AUTOSAR XML (schema 4-3-0)
package /Impl_SWC_CDD_ARPkg
  swc implementation Impl_SWC_CDD_type: programming-language=C, sw-version=1.0.0, vendor-id=0, behavior=SWC_CDD_type_IB
    code-descriptors:
      code SRC: artifact-descriptors=autosar-engineering-object={short-label=EngObject, category=SWSRC}
    resource consumption ResourceConsumption
      memory section Mem_SWC_CDD_CODE: size=0, sw-addrmethod=CODE, symbol=CODE
package /SWC_CDD_ARPkg
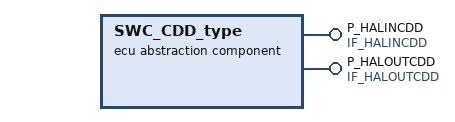
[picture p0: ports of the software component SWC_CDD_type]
  ecu abstraction sw component type SWC_CDD_type
    provide port P_HALINCDD: provided-interface=IF_HALINCDD
    provide port P_HALOUTCDD: provided-interface=IF_HALOUTCDD
    behavior SWC_CDD_type_IB: handle-termination-and-restart=NO-SUPPORT
      61 x operation invoked event:
        oie_P_HALINCDD_CSOP_apsGetDidRequest: start-on-event=run_HALINCDD_apsGetDidRequest, operation=P_HALINCDD.CSOP_apsGetDidRequest
        oie_P_HALINCDD_CSOP_dkcGetDidRequest: start-on-event=run_HALINCDD_dkcGetDidRequest, operation=P_HALINCDD.CSOP_dkcGetDidRequest
        oie_P_HALINCDD_CSOP_zevGetDidRequest: start-on-event=run_HALINCDD_zevGetDidRequest, operation=P_HALINCDD.CSOP_zevGetDidRequest
        oie_P_HALINCDD_CSOP_tpmGetDidRequest: start-on-event=run_HALINCDD_tpmGetDidRequest, operation=P_HALINCDD.CSOP_tpmGetDidRequest
        oie_P_HALINCDD_CSOP_bcmGetDidRequest: start-on-event=run_HALINCDD_bcmGetDidRequest, operation=P_HALINCDD.CSOP_bcmGetDidRequest
        oie_P_HALINCDD_CSOP_vcuGetDidRequest: start-on-event=run_HALINCDD_vcuGetDidRequest, operation=P_HALINCDD.CSOP_vcuGetDidRequest
        oie_P_HALINCDD_CSOP_dkcIsDidRequested: start-on-event=run_HALINCDD_dkcIsDidRequested, operation=P_HALINCDD.CSOP_dkcIsDidRequested
        oie_P_HALINCDD_CSOP_zevIsDidRequested: start-on-event=run_HALINCDD_zevIsDidRequested, operation=P_HALINCDD.CSOP_zevIsDidRequested
        oie_P_HALINCDD_CSOP_apsIsDidRequested: start-on-event=run_HALINCDD_apsIsDidRequested, operation=P_HALINCDD.CSOP_apsIsDidRequested
        oie_P_HALINCDD_CSOP_tpmIsDidRequested: start-on-event=run_HALINCDD_tpmIsDidRequested, operation=P_HALINCDD.CSOP_tpmIsDidRequested
        oie_P_HALINCDD_CSOP_bcmIsDidRequested: start-on-event=run_HALINCDD_bcmIsDidRequested, operation=P_HALINCDD.CSOP_bcmIsDidRequested
        oie_P_HALINCDD_CSOP_vcuIsDidRequested: start-on-event=run_HALINCDD_vcuIsDidRequested, operation=P_HALINCDD.CSOP_vcuIsDidRequested
        oie_P_HALINCDD_CSOP_nmGetCan6TxErrorCount: start-on-event=run_HALINCDD_nmGetCan6TxErrorCount, operation=P_HALINCDD.CSOP_nmGetCan6TxErrorCount
        oie_P_HALINCDD_CSOP_nmGetCan6RxErrorCount: start-on-event=run_HALINCDD_nmGetCan6RxErrorCount, operation=P_HALINCDD.CSOP_nmGetCan6RxErrorCount
        oie_P_HALINCDD_CSOP_nmGetCan5TxErrorCount: start-on-event=run_HALINCDD_nmGetCan5TxErrorCount, operation=P_HALINCDD.CSOP_nmGetCan5TxErrorCount
        oie_P_HALINCDD_CSOP_nmGetCan5RxErrorCount: start-on-event=run_HALINCDD_nmGetCan5RxErrorCount, operation=P_HALINCDD.CSOP_nmGetCan5RxErrorCount
        oie_P_HALINCDD_CSOP_nmGetCan4TxErrorCount: start-on-event=run_HALINCDD_nmGetCan4TxErrorCount, operation=P_HALINCDD.CSOP_nmGetCan4TxErrorCount
        oie_P_HALINCDD_CSOP_nmGetCan4RxErrorCount: start-on-event=run_HALINCDD_nmGetCan4RxErrorCount, operation=P_HALINCDD.CSOP_nmGetCan4RxErrorCount
        oie_P_HALINCDD_CSOP_nmGetCan3TxErrorCount: start-on-event=run_HALINCDD_nmGetCan3TxErrorCount, operation=P_HALINCDD.CSOP_nmGetCan3TxErrorCount
        oie_P_HALINCDD_CSOP_nmGetCan3RxErrorCount: start-on-event=run_HALINCDD_nmGetCan3RxErrorCount, operation=P_HALINCDD.CSOP_nmGetCan3RxErrorCount
        oie_P_HALINCDD_CSOP_nmGetCan2TxErrorCount: start-on-event=run_HALINCDD_nmGetCan2TxErrorCount, operation=P_HALINCDD.CSOP_nmGetCan2TxErrorCount
        oie_P_HALINCDD_CSOP_nmGetCan2RxErrorCount: start-on-event=run_HALINCDD_nmGetCan2RxErrorCount, operation=P_HALINCDD.CSOP_nmGetCan2RxErrorCount
        oie_P_HALINCDD_CSOP_nmGetCan1TxErrorCount: start-on-event=run_HALINCDD_nmGetCan1TxErrorCount, operation=P_HALINCDD.CSOP_nmGetCan1TxErrorCount
        oie_P_HALINCDD_CSOP_nmGetCan1RxErrorCount: start-on-event=run_HALINCDD_nmGetCan1RxErrorCount, operation=P_HALINCDD.CSOP_nmGetCan1RxErrorCount
        oie_P_HALINCDD_CSOP_AnyNmID: start-on-event=run_HALINCDD_AnyNMID, operation=P_HALINCDD.CSOP_AnyNmID
        oie_P_HALINCDD_CSOP_GetAcoreRebootCmd: start-on-event=run_HALINCDD_GetAcoreRebootCmd, operation=P_HALINCDD.CSOP_GetAcoreRebootCmd
        oie_P_HALOUTCDD_CSOP_SetAcoreRebootCmdACK: start-on-event=run_HALOUTCDD_SetAcoreRebootCmdACK, operation=P_HALOUTCDD.CSOP_SetAcoreRebootCmdACK
        oie_P_HALINCDD_CSOP_ReadPedalZeroPosReq: start-on-event=run_HALINCDD_ReadPedalZeroPosReq, operation=P_HALINCDD.CSOP_ReadPedalZeroPosReq
        oie_P_HALINCDD_CSOP_ResetPedalZeroPosReq: start-on-event=run_HALINCDD_ResetPedalZeroPosReq, operation=P_HALINCDD.CSOP_ResetPedalZeroPosReq
        oie_P_HALINCDD_CSOP_ResetPedalZeroPosDone: start-on-event=run_HALINCDD_ResetPedalZeroPosDone, operation=P_HALOUTCDD.CSOP_ResetPedalZeroPosDone
        oie_P_HALINCDD_CSOP_TPMSSensorIDRegGetSta: start-on-event=run_HALINCDD_TPMSSensorIDRegGetSta, operation=P_HALINCDD.CSOP_TPMSSensorIDRegGetSta
        oie_P_HALINCDD_CSOP_TPMSSensorIDRegSetResults: start-on-event=run_HALINCDD_TPMSSensorIDRegSetResults, operation=P_HALOUTCDD.CSOP_TPMSSensorIDRegSetResults
        oie_P_HALINCDD_CSOP_CAN{1..6}BusOff: start-on-event=run_HALINCDD_CAN{1..6}BusOff, operation=P_HALINCDD.CSOP_CAN{1..6}BusOff
        oie_P_HALINCDD_CSOP_DIDgetDKCdata: start-on-event=run_HALINCDD_DIDgetDKCdata, operation=P_HALINCDD.CSOP_DIDgetDKCdata
        oie_P_HALINCDD_CSOP_DKCDecrypt: start-on-event=run_HALINCDD_DKCDecrypt, operation=P_HALINCDD.CSOP_DKCDecrypt
        oie_P_HALINCDD_CSOP_GetACoreReadyToSleep: start-on-event=run_HALINCDD_GetACoreReadyToSleep, operation=P_HALINCDD.CSOP_GetAcoreReadyToSleep
        oie_P_HALINCDD_CSOP_GetAuxBattVoltage: start-on-event=run_HALINCDD_GetAuxBattVoltage, operation=P_HALINCDD.CSOP_GetAuxBattVoltage
        oie_P_HALINCDD_CSOP_GetBootReason: start-on-event=run_HALINCDD_GetBootReason, operation=P_HALINCDD.CSOP_GetBootReason
        oie_P_HALINCDD_CSOP_GetBootPath: start-on-event=run_HALINCDD_GetBootPath, operation=P_HALINCDD.CSOP_GetBootPath
        oie_P_HALINCDD_CSOP_GetDIDdata: start-on-event=run_HALINCDD_DIDgetXWDdata, operation=P_HALINCDD.CSOP_DIDgetXWDdata
        oie_P_HALINCDD_CSOP_GetEvccAplusPwrUpReq: start-on-event=run_HALINCDD_GetEvccAplusPwrUpReq, operation=P_HALINCDD.CSOP_GetEvccAplusPwrUpReq
        oie_P_HALINCDD_CSOP_GetHWID: start-on-event=run_HALINCDD_GetHWID, operation=P_HALINCDD.u8Array4_HWID
        oie_P_HALINCDD_CSOP_GetNmState: start-on-event=run_HALINCDD_GetNmState, operation=P_HALINCDD.CSOP_GetNmState
        oie_P_HALINCDD_CSOP_GetNvmProtectState: start-on-event=run_HALINCDD_GetNvmProtectState, operation=P_HALINCDD.CSOP_GetNvmProtectState
        oie_P_HALINCDD_CSOP_GetSWID: start-on-event=run_HALINCDD_GetSWID, operation=P_HALINCDD.CSOP_GetSWID
        oie_P_HALINCDD_CSOP_GetVinCode: start-on-event=run_HALINCDD_GetVinCode, operation=P_HALINCDD.CSOP_GetVinCode
        oie_P_HALINCDD_CSOP_GetVinpAllowMoveThdOta: start-on-event=run_HALINCDD_GetAllowMoveThdOta, operation=P_HALINCDD.CSOP_GetVinpAllowMoveThdOta
        oie_P_HALINCDD_CSOP_GetVinpPwrReqOta: start-on-event=run_HALINCDD_GetPwrReqOta, operation=P_HALINCDD.CSOP_GetVinpPwrReqOta
        oie_P_HALINCDD_CSOP_GetWISR: start-on-event=run_HALINCDD_GetWISR, operation=P_HALINCDD.CSOP_GetWISR
        oie_P_HALINCDD_CSOP_HALINCDD_DIRECT: start-on-event=run_HALINCDD_DIRECT, operation=P_HALINCDD.CSOP_HALINCDD_DIRECT
        oie_P_HALINCDD_CSOP_IPCF_Handler: start-on-event=run_HALINCDD_IPCF_Handler, operation=P_HALINCDD.CSOP_IPCF_Handler
        oie_P_HALINCDD_CSOP_UDS_Main: start-on-event=run_UDS_Handler, operation=P_HALINCDD.CSOP_UDS_Main
        oie_P_HALOUTCDD_CSOP_AppNmStateReq: start-on-event=run_HALOUTCDD_AppNmStateReq, operation=P_HALOUTCDD.CSOP_AppNmStateReq
        oie_P_HALOUTCDD_CSOP_SetHazardIND: start-on-event=run_HALOUTCDD_SetHazardIND, operation=P_HALOUTCDD.CSOP_SetHazardIND
        oie_P_HALOUTCDD_CSOP_SetSysPwrStat: start-on-event=run_HALOUTCDD_SetSysPwrStat, operation=P_HALOUTCDD.CSOP_SetSysPwrStat
        oie_P_HALOUTCDD_CSOP_SleepRequest: start-on-event=run_HALOUTCDD_SleepRequest, operation=P_HALOUTCDD.CSOP_SleepRequest
      port-api-options:
        enable-take-address=false, indirect-api=false, port=P_HALINCDD
        enable-take-address=false, indirect-api=false, port=P_HALOUTCDD
      61 x runnable:
        run_HALINCDD_apsGetDidRequest
        run_HALINCDD_dkcGetDidRequest
        run_HALINCDD_zevGetDidRequest
        run_HALINCDD_tpmGetDidRequest
        run_HALINCDD_bcmGetDidRequest
        run_HALINCDD_vcuGetDidRequest
        run_HALINCDD_dkcIsDidRequested
        run_HALINCDD_zevIsDidRequested
        run_HALINCDD_apsIsDidRequested
        run_HALINCDD_tpmIsDidRequested
        run_HALINCDD_bcmIsDidRequested
        run_HALINCDD_vcuIsDidRequested
        run_HALINCDD_nmGetCan6TxErrorCount
        run_HALINCDD_nmGetCan6RxErrorCount
        run_HALINCDD_nmGetCan5TxErrorCount
        run_HALINCDD_nmGetCan5RxErrorCount
        run_HALINCDD_nmGetCan4TxErrorCount
        run_HALINCDD_nmGetCan4RxErrorCount
        run_HALINCDD_nmGetCan3TxErrorCount
        run_HALINCDD_nmGetCan3RxErrorCount
        run_HALINCDD_nmGetCan2TxErrorCount
        run_HALINCDD_nmGetCan2RxErrorCount
        run_HALINCDD_nmGetCan1TxErrorCount
        run_HALINCDD_nmGetCan1RxErrorCount
        run_HALINCDD_AnyNMID
        run_HALINCDD_GetAcoreRebootCmd
        run_HALOUTCDD_SetAcoreRebootCmdACK
        run_HALINCDD_ReadPedalZeroPosReq
        run_HALINCDD_ResetPedalZeroPosReq
        run_HALINCDD_ResetPedalZeroPosDone
        run_HALINCDD_TPMSSensorIDRegGetSta
        run_HALINCDD_TPMSSensorIDRegSetResults
        run_HALINCDD_CAN{1..6}BusOff
        run_HALINCDD_DIDgetDKCdata: symbol=run_DIDgetDKCdata
        run_HALINCDD_DIDgetXWDdata: symbol=run_HALINCDD_GetDIDdata
        run_HALINCDD_DIRECT
        run_HALINCDD_DKCDecrypt
        run_HALINCDD_GetACoreReadyToSleep
        run_HALINCDD_GetAllowMoveThdOta: symbol=run_GetAllowMoveThdOta
        run_HALINCDD_GetAuxBattVoltage
        run_HALINCDD_GetBootReason
        run_HALINCDD_GetBootPath
        run_HALINCDD_GetEvccAplusPwrUpReq
        run_HALINCDD_GetHWID
        run_HALINCDD_GetNmState
        run_HALINCDD_GetNvmProtectState
        run_HALINCDD_GetPwrReqOta
        run_HALINCDD_GetSWID
        run_HALINCDD_GetVinCode
        run_HALINCDD_GetWISR
        run_HALINCDD_IPCF_Handler
        run_HALOUTCDD_AppNmStateReq
        run_HALOUTCDD_SetHazardIND
        run_HALOUTCDD_SetSysPwrStat
        run_HALOUTCDD_SleepRequest
        run_UDS_Handler
